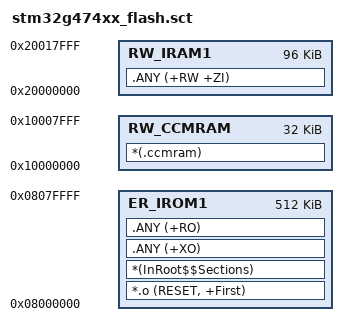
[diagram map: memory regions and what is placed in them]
; *********************************************************************************
; *** Scatter-Loading Description File generated by STM32CubeMX/LinkerGenerator ***
; *********************************************************************************;
;
; [P0-9] 修正 RAM 尺寸
;   STM32G474RET6 实际内存（DS12288 Rev 4）:
;     SRAM : 96 KB @ 0x20000000 .. 0x20017FFF   (DMA 可达)
;     CCM  : 32 KB @ 0x10000000 .. 0x10007FFF   (DMA 不可达, CPU 零等待)
;   原文件误写 0x00020000 (128KB) @ 0x20000000, 会越界到不存在的地址
;
;   分区策略:
;     RW_IRAM1 (SRAM)  : 放置 DMA 缓冲区 + 全局数据
;     RW_CCMRAM (CCM)  : 放置栈与非 DMA 数据, 不占用 DMA 区
;
LR_IROM1 0x8000000 0x00080000  {  ; load_region size_region
  ER_IROM1 0x8000000 0x00080000  {  ; load address = exception address
   *.o (RESET, +First)
   *(InRoot$$Sections)
   .ANY (+XO)
   .ANY (+RO)
  }
  RW_IRAM1 0x20000000 0x00018000  {  ; 96 KB SRAM (DMA 可达)
   .ANY (+RW +ZI)
  }
  RW_CCMRAM 0x10000000 0x00008000  {  ; 32 KB CCM (DMA 不可达)
   *(.ccmram)
  }
}


/*-Start of  regions- Auto-generated By STM32CubeMX-*/
